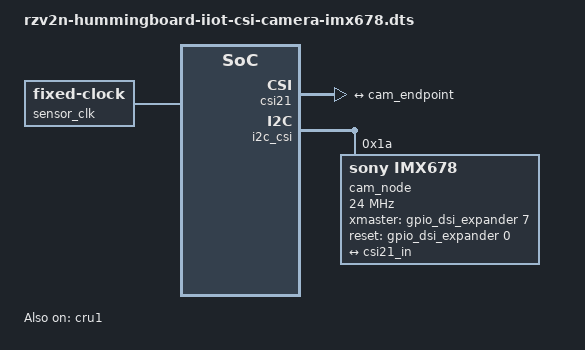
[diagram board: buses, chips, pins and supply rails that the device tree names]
// SPDX-License-Identifier: (GPL-2.0-only OR BSD-2-Clause)
/*
 * Device Tree Source for the RZ/V2N SolidRun HummingBoard IIoT
 *
 * Copyright (C) 2025 SolidRun Ltd.
 *
 * Overlay for enabling HummingBoard IIoT MIPI-CSI connector
 * with mipi-csi camera sony imx678.
 */

/dts-v1/;
/plugin/;

#include <dt-bindings/gpio/gpio.h>
#include <dt-bindings/interrupt-controller/irq.h>

&{/} {
    sensor_clk: sensor_clk {
        compatible = "fixed-clock";
        #clock-cells = <0>;
        clock-frequency = <24000000>;
    };
};

&cru1 {
	status = "okay";
};

&csi21 {
	status = "okay";
	ports {
		#address-cells = <1>;
		#size-cells = <0>;
		port@0 {
			reg = <0>;
			csi21_in: endpoint {
				remote-endpoint = <&cam_endpoint>;
				clock-lanes = <0>;
				data-lanes = <1 2 3 4>;
			};
		};
	};
};

&i2c_csi {
	#address-cells = <1>;
	#size-cells = <0>;

	cam_node: imx678@1a {
		compatible = "sony,imx678";
		reg = <0x1a>;
		status = "okay";

		rotation = <0>;
		orientation = <0>;

		clocks = <&sensor_clk>;
		clock-names = "inclk";
		clock-frequency = <24000000>;

		xmaster-gpios = <&gpio_dsi_expander 7 GPIO_ACTIVE_HIGH>; /* CAM_TRIG U48_IO7 */
		reset-gpios = <&gpio_dsi_expander 0 GPIO_ACTIVE_HIGH>;

		port {
			cam_endpoint: endpoint {
				remote-endpoint = <&csi21_in>;
				clock-lanes = <0>;
				data-lanes = <1 2 3 4>;
				link-frequencies = /bits/ 64 <891000000 1440000000 1782000000>;
			};
		};
	};
};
